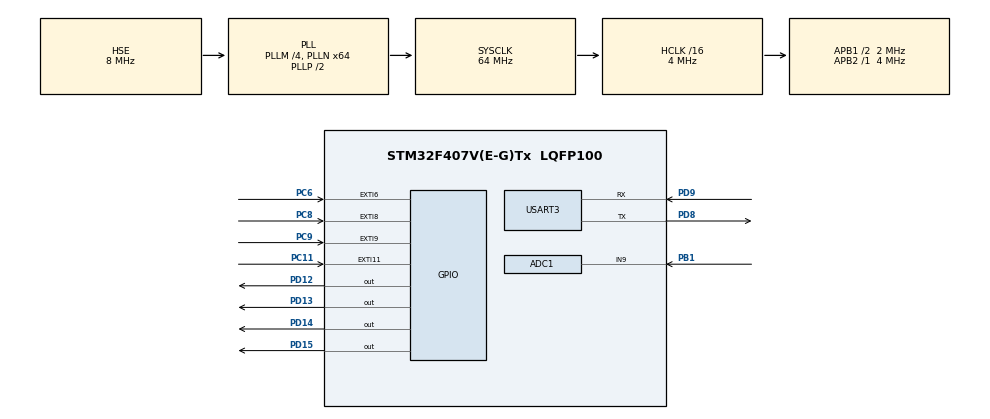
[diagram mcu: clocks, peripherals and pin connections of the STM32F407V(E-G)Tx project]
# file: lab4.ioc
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ADC1.Channel-0\#ChannelRegularConversion=ADC_CHANNEL_9
ADC1.NbrOfConversionFlag=1
ADC1.Rank-0\#ChannelRegularConversion=1
ADC1.SamplingTime-0\#ChannelRegularConversion=ADC_SAMPLETIME_480CYCLES
ADC1.ScanConvMode=ENABLE
ADC1.master=1
Mcu.Family=STM32F4
Mcu.Name=STM32F407V(E-G)Tx
Mcu.Package=LQFP100
NVIC.EXTI15_10_IRQn=true\:0\:0\:false\:false\:true\:true\:true\:true
NVIC.EXTI9_5_IRQn=true\:0\:0\:false\:false\:true\:true\:true\:true
NVIC.PriorityGroup=NVIC_PRIORITYGROUP_4
PB1.Signal=ADCx_IN9
PC11.GPIO_ModeDefaultEXTI=GPIO_MODE_IT_FALLING
PC11.Signal=GPXTI11
PC6.GPIO_ModeDefaultEXTI=GPIO_MODE_IT_FALLING
PC6.Signal=GPXTI6
PC8.GPIO_ModeDefaultEXTI=GPIO_MODE_IT_FALLING
PC8.Signal=GPXTI8
PC9.GPIO_ModeDefaultEXTI=GPIO_MODE_IT_FALLING
PC9.Signal=GPXTI9
PD12.GPIO_PuPd=GPIO_PULLDOWN
PD12.Signal=GPIO_Output
PD13.GPIO_PuPd=GPIO_PULLDOWN
PD13.Signal=GPIO_Output
PD14.GPIO_PuPd=GPIO_PULLDOWN
PD14.Signal=GPIO_Output
PD15.GPIO_PuPd=GPIO_PULLDOWN
PD15.Signal=GPIO_Output
PD8.Mode=Asynchronous
PD8.Signal=USART3_TX
PD9.Mode=Asynchronous
PD9.Signal=USART3_RX
PH0-OSC_IN.Mode=HSE-External-Oscillator
PH0-OSC_IN.Signal=RCC_OSC_IN
PH1-OSC_OUT.Mode=HSE-External-Oscillator
PH1-OSC_OUT.Signal=RCC_OSC_OUT
ProjectManager.HeapSize=0x200
ProjectManager.StackSize=0x400
ProjectManager.TargetToolchain=STM32CubeIDE
RCC.48MHZClocksFreq_Value=32000000
RCC.AHBCLKDivider=RCC_SYSCLK_DIV16
RCC.AHBFreq_Value=4000000
RCC.APB1CLKDivider=RCC_HCLK_DIV2
RCC.APB1Freq_Value=2000000
RCC.APB1TimFreq_Value=4000000
RCC.APB2Freq_Value=4000000
RCC.APB2TimFreq_Value=4000000
RCC.CortexFreq_Value=4000000
RCC.HCLKFreq_Value=4000000
RCC.HSE_VALUE=8000000
RCC.HSI_VALUE=16000000
RCC.LSE_VALUE=32768
RCC.PLLM=4
RCC.PLLN=64
RCC.PLLSourceVirtual=RCC_PLLSOURCE_HSE
RCC.SYSCLKFreq_VALUE=64000000
RCC.SYSCLKSource=RCC_SYSCLKSOURCE_PLLCLK
RCC.VCOOutputFreq_Value=128000000
SH.ADCx_IN9.0=ADC1_IN9,IN9
USART3.VirtualMode=VM_ASYNC
board=custom

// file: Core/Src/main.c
/* USER CODE BEGIN Header */
/**
  ******************************************************************************
  * @file           : main.c
  * @brief          : Main program body
  ******************************************************************************
  * @attention
  *
  * Copyright (c) 2023 STMicroelectronics.
  * All rights reserved.
  *
  * This software is licensed under terms that can be found in the LICENSE file
  * in the root directory of this software component.
  * If no LICENSE file comes with this software, it is provided AS-IS.
  *
  ******************************************************************************
  */
/* USER CODE END Header */
#include "main.h"

/* USER CODE BEGIN Includes */
#include "uart_control.h"
/* USER CODE END Includes */

ADC_HandleTypeDef hadc1;

UART_HandleTypeDef huart3;

/* USER CODE BEGIN PV */
uint32_t last_time = 0;
/* USER CODE END PV */

void SystemClock_Config(void);
static void MX_GPIO_Init(void);
static void MX_USART3_UART_Init(void);
static void MX_ADC1_Init(void);

int main(void)
{

  /* MCU Configuration--------------------------------------------------------*/

  /* Reset of all peripherals, Initializes the Flash interface and the Systick. */
  HAL_Init();

  /* Configure the system clock */
  SystemClock_Config();

  /* Initialize all configured peripherals */
  MX_GPIO_Init();
  MX_USART3_UART_Init();
  MX_ADC1_Init();

  /* Infinite loop */
  /* USER CODE BEGIN WHILE */
  while (1)
  {
	  if (HAL_GetTick() - last_time > 5000) {
		  last_time = HAL_GetTick();
		  ext_temp_sensor();
	  }
	  uart();
    /* USER CODE END WHILE */

  }
}

void SystemClock_Config(void)
{
  RCC_OscInitTypeDef RCC_OscInitStruct = {0};
  RCC_ClkInitTypeDef RCC_ClkInitStruct = {0};

  /** Configure the main internal regulator output voltage
  */
  __HAL_RCC_PWR_CLK_ENABLE();
  __HAL_PWR_VOLTAGESCALING_CONFIG(PWR_REGULATOR_VOLTAGE_SCALE1);

  /** Initializes the RCC Oscillators according to the specified parameters
  * in the RCC_OscInitTypeDef structure.
  */
  RCC_OscInitStruct.OscillatorType = RCC_OSCILLATORTYPE_HSE;
  RCC_OscInitStruct.HSEState = RCC_HSE_ON;
  RCC_OscInitStruct.PLL.PLLState = RCC_PLL_ON;
  RCC_OscInitStruct.PLL.PLLSource = RCC_PLLSOURCE_HSE;
  RCC_OscInitStruct.PLL.PLLM = 4;
  RCC_OscInitStruct.PLL.PLLN = 64;
  RCC_OscInitStruct.PLL.PLLP = RCC_PLLP_DIV2;
  RCC_OscInitStruct.PLL.PLLQ = 4;
  if (HAL_RCC_OscConfig(&RCC_OscInitStruct) != HAL_OK)
  {
    Error_Handler();
  }

  /** Initializes the CPU, AHB and APB buses clocks
  */
  RCC_ClkInitStruct.ClockType = RCC_CLOCKTYPE_HCLK|RCC_CLOCKTYPE_SYSCLK
                              |RCC_CLOCKTYPE_PCLK1|RCC_CLOCKTYPE_PCLK2;
  RCC_ClkInitStruct.SYSCLKSource = RCC_SYSCLKSOURCE_PLLCLK;
  RCC_ClkInitStruct.AHBCLKDivider = RCC_SYSCLK_DIV16;
  RCC_ClkInitStruct.APB1CLKDivider = RCC_HCLK_DIV2;
  RCC_ClkInitStruct.APB2CLKDivider = RCC_HCLK_DIV1;

  if (HAL_RCC_ClockConfig(&RCC_ClkInitStruct, FLASH_LATENCY_0) != HAL_OK)
  {
    Error_Handler();
  }
}

static void MX_ADC1_Init(void)
{

  ADC_ChannelConfTypeDef sConfig = {0};

  /** Configure the global features of the ADC (Clock, Resolution, Data Alignment and number of conversion)
  */
  hadc1.Instance = ADC1;
  hadc1.Init.ClockPrescaler = ADC_CLOCK_SYNC_PCLK_DIV2;
  hadc1.Init.Resolution = ADC_RESOLUTION_12B;
  hadc1.Init.ScanConvMode = ENABLE;
  hadc1.Init.ContinuousConvMode = DISABLE;
  hadc1.Init.DiscontinuousConvMode = DISABLE;
  hadc1.Init.ExternalTrigConvEdge = ADC_EXTERNALTRIGCONVEDGE_NONE;
  hadc1.Init.ExternalTrigConv = ADC_SOFTWARE_START;
  hadc1.Init.DataAlign = ADC_DATAALIGN_RIGHT;
  hadc1.Init.NbrOfConversion = 1;
  hadc1.Init.DMAContinuousRequests = DISABLE;
  hadc1.Init.EOCSelection = ADC_EOC_SINGLE_CONV;
  if (HAL_ADC_Init(&hadc1) != HAL_OK)
  {
    Error_Handler();
  }

  /** Configure for the selected ADC regular channel its corresponding rank in the sequencer and its sample time.
  */
  sConfig.Channel = ADC_CHANNEL_9;
  sConfig.Rank = 1;
  sConfig.SamplingTime = ADC_SAMPLETIME_480CYCLES;
  if (HAL_ADC_ConfigChannel(&hadc1, &sConfig) != HAL_OK)
  {
    Error_Handler();
  }

}

static void MX_USART3_UART_Init(void)
{

  huart3.Instance = USART3;
  huart3.Init.BaudRate = 115200;
  huart3.Init.WordLength = UART_WORDLENGTH_8B;
  huart3.Init.StopBits = UART_STOPBITS_1;
  huart3.Init.Parity = UART_PARITY_NONE;
  huart3.Init.Mode = UART_MODE_TX_RX;
  huart3.Init.HwFlowCtl = UART_HWCONTROL_NONE;
  huart3.Init.OverSampling = UART_OVERSAMPLING_16;
  if (HAL_UART_Init(&huart3) != HAL_OK)
  {
    Error_Handler();
  }

}

static void MX_GPIO_Init(void)
{
  GPIO_InitTypeDef GPIO_InitStruct = {0};

  /* GPIO Ports Clock Enable */
  __HAL_RCC_GPIOH_CLK_ENABLE();
  __HAL_RCC_GPIOB_CLK_ENABLE();
  __HAL_RCC_GPIOD_CLK_ENABLE();
  __HAL_RCC_GPIOC_CLK_ENABLE();

  /*Configure GPIO pin Output Level */
  HAL_GPIO_WritePin(GPIOD, GPIO_PIN_12|GPIO_PIN_13|GPIO_PIN_14|GPIO_PIN_15, GPIO_PIN_RESET);

  /*Configure GPIO pins : PD12 PD13 PD14 PD15 */
  GPIO_InitStruct.Pin = GPIO_PIN_12|GPIO_PIN_13|GPIO_PIN_14|GPIO_PIN_15;
  GPIO_InitStruct.Mode = GPIO_MODE_OUTPUT_PP;
  GPIO_InitStruct.Pull = GPIO_PULLDOWN;
  GPIO_InitStruct.Speed = GPIO_SPEED_FREQ_LOW;
  HAL_GPIO_Init(GPIOD, &GPIO_InitStruct);

  /*Configure GPIO pins : PC6 PC8 PC9 PC11 */
  GPIO_InitStruct.Pin = GPIO_PIN_6|GPIO_PIN_8|GPIO_PIN_9|GPIO_PIN_11;
  GPIO_InitStruct.Mode = GPIO_MODE_IT_FALLING;
  GPIO_InitStruct.Pull = GPIO_NOPULL;
  HAL_GPIO_Init(GPIOC, &GPIO_InitStruct);

  /* EXTI interrupt init*/
  HAL_NVIC_SetPriority(EXTI9_5_IRQn, 0, 0);
  HAL_NVIC_EnableIRQ(EXTI9_5_IRQn);

  HAL_NVIC_SetPriority(EXTI15_10_IRQn, 0, 0);
  HAL_NVIC_EnableIRQ(EXTI15_10_IRQn);

}

void Error_Handler(void)
{
  __disable_irq();
  while (1)
  {
  }
}
